# STM32WL5X_CM0P register map
File version: 2.1
CPU: CM0 r0p1, little endian, MPU, no FPU, 4 interrupt priority bits
Registers are 32-bit, read-write, reset 0x0 unless marked. A register's access mark holds for its fields unless they carry their own. Offsets are from the block's base; [hi:lo] are bit positions; {n}, {i} and the like mark numbered series; 'fields as' and 'values as' point back to an identical list.

## PWR — Power control
Base 0x58000400
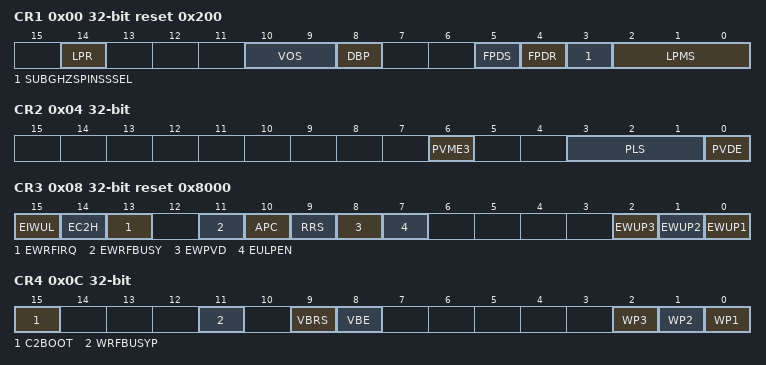
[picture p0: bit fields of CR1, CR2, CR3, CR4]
0x00 CR1 reset 0x200 — Power control register 1
  [14] LPR — Low-power run
    0=MainMode (Voltage regulator in Main mode in Low-power run mode); 1=LowPowerMode (Voltage regulator in low-power mode in Low-power run mode)
  [10:9] VOS — Voltage scaling range selection
    1=V1_2 (1.2 V (range 1)); 2=V1_0 (1.0 V (range 2))
  [8] DBP — Disable backup domain write protection
    0=Disabled (Access to RTC and backup registers disabled); 1=Enabled (Access to RTC and backup registers enabled)
  [5] FPDS — Flash memory power down mode during LPSleep for CPU1
    0=Idle (Flash memory in Idle mode when system is in LPSleep mode); 1=PowerDown (Flash memory in Power-down mode when system is in LPSleep mode)
  [4] FPDR — Flash memory power down mode during LPRun for CPU1
    0=Idle (Flash memory in Idle mode when system is in LPRun mode); 1=PowerDown (Flash memory in Power-down mode when system is in LPRun mode)
  [3] SUBGHZSPINSSSEL — sub-GHz SPI NSS source select
    0=SUBGHZSPICR (sub-GHz SPI NSS signal driven from PWR_SUBGHZSPICR.NSS (RFBUSYMS functionality enabled)); 1=LPTIM3 (sub-GHz SPI NSS signal driven from LPTIM3_OUT (RFBUSYMS functionality disabled))
  [2:0] LPMS — Low-power mode selection for CPU1
    0=Stop 0 mode; 1=Stop 1 mode; 2=Stop 2 mode; 3=Standby mode; 4=Shutdown mode
0x04 CR2 — Power control register 2
  [6] PVME3 — Peripheral voltage monitoring 3 enable: VDDA vs. 1.62V
    0=Disabled (PVM3 (VDDA monitoring versus 1.62 V threshold) disable); 1=Enabled (PVM3 (VDDA monitoring versus 1.62 V threshold) enable)
  [3:1] PLS — Power voltage detector level selection.
    0=V2_0 (2.0V); 1=V2_2 (2.2V); 2=V2_4 (2.4V); 3=V2_5 (2.5V); 4=V2_6 (2.6V); 5=V2_8 (2.8V); 6=V2_9 (2.9V); 7=External input analog voltage PVD_IN (compared internally to VREFINT)
  [0] PVDE — Power voltage detector enable
    0=Disabled (PVD Disabled); 1=Enabled (PVD Enabled)
0x08 CR3 reset 0x8000 — Power control register 3
  [15] EIWUL — Enable internal wakeup line for CPU1
    0=Disabled (Internal wakeup line interrupt to CPU1 disabled); 1=Enabled (Internal wakeup line interrupt to CPU1 enabled)
  [14] EC2H — nable CPU2 Hold interrupt for CPU1
  [13] EWRFIRQ — akeup for CPU1
    0=Disabled (Radio IRQ[2:0] is disabled and does not trigger a wakeup from Standby event to CPU1.); 1=Enabled (Radio IRQ[2:0] is enabled and triggers a wakeup from Standby event to CPU1.)
  [11] EWRFBUSY — Enable Radio BUSY Wakeup from Standby for CPU1
    0=Disabled (Radio Busy is disabled and does not trigger a wakeup from Standby event to CPU1 when a rising or a falling edge occurs); 1=Enabled (Radio Busy is enabled and triggers a wakeup from Standby event to CPU1 when a rising or a falling edge occurs. The active edge is configured via the WRFBUSYP bit in PWR_CR4)
  [10] APC — Apply pull-up and pull-down configuration from CPU1
    0=Disabled (I/O pull-up and pull-down configurations defined in the PWR_PUCRx and PWR_PDCRx registers are applied); 1=Enabled (PWR_PUCRx and PWR_PDCRx registers are NOT applied to the I/Os)
  [9] RRS — SRAM2 retention in Standby mode
    0=PowerOff (SRAM2 powered off in Standby mode (SRAM2 content lost)); 1=OnLPR (SRAM2 powered by the low-power regulator in Standby mode (SRAM2 content kept))
  [8] EWPVD — Enable wakeup PVD for CPU1
    0=Disabled (PVD not enabled by the sub-GHz radio active state); 1=Enabled (PVD enabled while the sub-GHz radio is active)
  [7] EULPEN — Ultra-low-power enable
    0=Disabled (Disable (the supply voltage is monitored continuously)); 1=Enabled (Enable, when set, the supply voltage is sampled for PDR/BOR reset condition only periodically)
  [2] EWUP3 — Enable Wakeup pin WKUP3 for CPU1
    0=Disabled (WKUP pin 3 is used for general purpose I/Os. An event on the WKUP pin 3 does not wakeup the device from Standby mode); 1=Enabled (WKUP pin 3 is used for wakeup from Standby mode and forced in input pull down configuration (rising edge on WKUP pin 3wakes-up the system from Standby mode))
  [1] EWUP2 — Enable Wakeup pin WKUP2 for CPU1
    0=Disabled (WKUP pin 2 is used for general purpose I/Os. An event on the WKUP pin 2 does not wakeup the device from Standby mode); 1=Enabled (WKUP pin 2 is used for wakeup from Standby mode and forced in input pull down configuration (rising edge on WKUP pin 2 wakes-up the system from Standby mode))
  [0] EWUP1 — Enable Wakeup pin WKUP1 for CPU1
    0=Disabled (WKUP pin 1 is used for general purpose I/Os. An event on the WKUP pin 1 does not wakeup the device from Standby mode); 1=Enabled (WKUP pin 1 is used for wakeup from Standby mode and forced in input pull down configuration (rising edge on WKUP pin 1 wakes-up the system from Standby mode))
0x0C CR4 — Power control register 4
  [15] C2BOOT — oot CPU2 after reset or wakeup from Stop or Standby modes.
  [11] WRFBUSYP — Wakeup Radio BUSY polarity
    0=RisingEdge (Detection on high level (rising edge)); 1=FallingEdge (Detection on low level (falling edge))
  [9] VBRS — VBAT battery charging resistor selection
    0=R5k (VBAT charging through a 5 kΩ resistor); 1=R1_5k (VBAT charging through a 1.5 kΩ resistor)
  [8] VBE — VBAT battery charging enable
    0=Disabled (VBAT battery charging disabled); 1=Enabled (VBAT battery charging enabled)
  [2] WP3 — Wakeup pin WKUP3 polarity
    values as WRFBUSYP
  [1] WP2 — Wakeup pin WKUP2 polarity
    values as WRFBUSYP
  [0] WP1 — Wakeup pin WKUP1 polarity
    values as WRFBUSYP
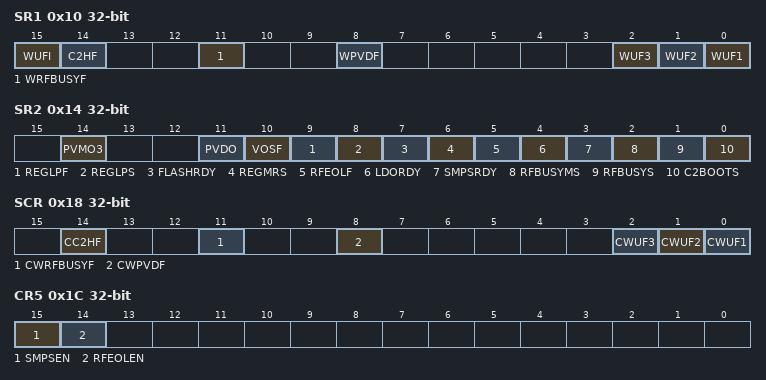
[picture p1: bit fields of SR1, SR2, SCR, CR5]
0x10 SR1 ro — Power status register 1
  [15] WUFI — Internal wakeup interrupt flag
    0=Clear (All internal wakeup sources are cleared); 1=wakeup is detected on the internal wakeup line
  [14] C2HF — PU2 Hold interrupt flag
  [11] WRFBUSYF — Radio BUSY wakeup flag
    0=Clear (No wakeup event detected on radio busy); 1=Wakeup event detected on radio busy
  [8] WPVDF — Wakeup PVD flag
    0=Clear (No wakeup event detected on PVD); 1=Wakeup event detected on PVD
  [2] WUF3 — Wakeup flag 3
    0=Clear (No wakeup event detected on WKUP3); 1=Wakeup event detected on WKUP3
  [1] WUF2 — Wakeup flag 2
    0=Clear (No wakeup event detected on WKUP2); 1=Wakeup event detected on WKUP2
  [0] WUF1 — Wakeup flag 1
    0=Clear (No wakeup event detected on WKUP1); 1=Wakeup event detected on WKUP1
0x14 SR2 ro — Power status register 2
  [14] PVMO3 — Peripheral voltage monitoring output: VDDA vs. 1.62 V
    0=Above (VDDA voltage above PVM3 threshold (around 1.62 V)); 1=Below (VDDA voltage below PVM3 threshold (around 1.62 V))
  [11] PVDO — Power voltage detector output
    0=Above (VDD or voltage level on PVD_IN above the selected PVD threshold); 1=Below (VDD or voltage level on PVD_IN below the selected PVD threshold)
  [10] VOSF — Voltage scaling flag
    0=Ready (Regulator ready in the selected voltage range); 1=Change (Regulator output voltage changed to the required voltage level)
  [9] REGLPF — regulator1 low power flag
    0=Main regulator (MR) ready and used; 1=Low-power regulator (LPR) used
  [8] REGLPS — regulator1 started
    0=NotReady (LPR not ready); 1=Ready (LPR ready)
  [7] FLASHRDY — Flash ready
    0=NotReady (Flash memory not ready to be accessed); 1=Ready (Flash memory ready to be accessed)
  [6] REGMRS — regulator2 low power flag
    0=V_DD (Main regulator supplied directly from VDD); 1=LDO_SMPS (Main regulator supplied through LDO or SMPS)
  [5] RFEOLF — Radio end of life flag
    0=Above (Supply voltage above radio end-of-life operating low level); 1=Below (Supply voltage below radio end-of-life operating low level)
  [4] LDORDY — LDO ready flag
    0=NotReady (LDO not ready or off); 1=Ready (LDO ready)
  [3] SMPSRDY — SMPS ready flag
    0=NotReady (SMPS step-down converter not ready or off); 1=Ready (SMPS step-down converter ready)
  [2] RFBUSYMS — Radio BUSY masked signal status
    0=NotBusy (radio busy masked signal low (not busy)); 1=Busy (radio busy masked signal high (busy))
  [1] RFBUSYS — Radio BUSY signal status
    0=NotBusy (radio busy signal low (not busy)); 1=Busy (radio busy signal high (busy))
  [0] C2BOOTS — PU2 boot/wakeup request source information
0x18 SCR wo — Power status clear register
  [14] CC2HF — lear CPU2 Hold interrupt flag
  [11] CWRFBUSYF — Clear wakeup Radio BUSY flag
    1=Clear (Setting this bit clears the WRFBUSYF flag in the PWR_SR1. This bit is always read 0.)
  [8] CWPVDF — Clear wakeup PVD interrupt flag
    1=Clear (Setting this bit clears the WPVDF flag in the PWR_SR1. This bit is always read as 0.)
  [2] CWUF3 — Clear wakeup flag 3
    1=Clear (Setting this bit clears the WUF3 flag in the PWR_SR1 register. This bit is always read as 0.)
  [1] CWUF2 — Clear wakeup flag 2
    1=Clear (Setting this bit clears the WUF2 flag in the PWR_SR1 register. This bit is always read as 0.)
  [0] CWUF1 — Clear wakeup flag 1
    1=Clear (Setting this bit clears the WUF1 flag in the PWR_SR1 register. This bit is always read as 0.)
0x1C CR5 — Power control register 5
  [15] SMPSEN — Enable SMPS Step Down converter SMPS mode enabled.
    0=Disabled (SMPS step-down converter SMPS mode disabled (LDO mode enabled)); 1=Enabled (SMPS step-down converter SMPS mode enabled)
  [14] RFEOLEN — Enable Radio End Of Life detector enabled
    0=Disabled (Radio end-of-life detector disabled); 1=Enabled (Radio end-of-life detector enabled)
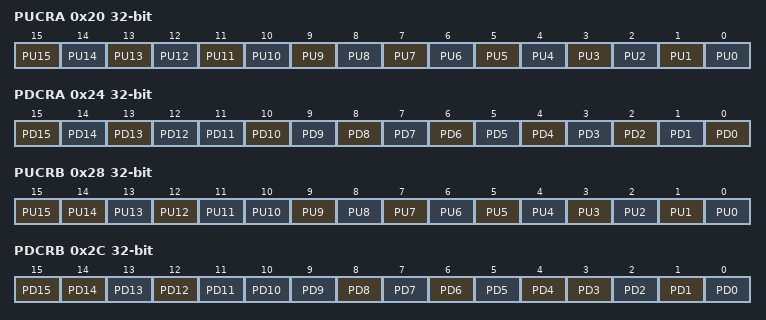
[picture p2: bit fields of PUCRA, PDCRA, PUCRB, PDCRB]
0x20 PUCRA — Power Port A pull-up control register
  [all] fields
    0=Disabled (Disable pull-up on PA[y] when both APC bits are set in PWR control register 3 (PWR_CR3)); 1=Enabled (Enable pull-up on PA[y] when both APC bits are set in PWR control register 3 (PWR_CR3). The pull-up is not activated if the corresponding PA[y] bit is also set)
  [15] PU15 — Port PA15 pull-up
  [14] PU14
  [13] PU13 — Port PA[y] pull-up bit y (y=0 to 13)
  [n] PU{n} (n=0..12)
0x24 PDCRA — Power Port A pull-down control register
  [all] fields
    0=Disabled (Disable the pull-down on PA[y] when both APC bits are set in PWR control register 3 (PWR_CR3)); 1=Enabled (Enable the pull-down on PA[y] when both APC bits are set in PWR control register 3 (PWR_CR3))
  [15] PD15
  [14] PD14 — ull-down
  [13] PD13
  [12] PD12 — Port PA[y] pull-down (y=0 to 12)
  [n] PD{n} (n=0..11)
0x28 PUCRB — Power Port B pull-up control register
  [15] PU15 — Port PB[y] pull-up (y=0 to 15)
    values as the fields of PUCRA
  [n] PU{n} (n=11..14)
    values as the fields of PUCRA
  [10] PU10
    0=Disabled (Disable pull-up on PB[y] when both APC bits are set in PWR control register 3 (PWR_CR3)); 1=Enabled (Enable pull-up on PB[y] when both APC bits are set in PWR control register 3 (PWR_CR3). The pull-up is not activated if the corresponding PB[y] bit is also set)
  [n] PU{n} (n=1..9)
    values as the fields of PUCRA
  [0] PU0
    values as PU10
0x2C PDCRB — Power Port B pull-down control register
  [15] PD15 — Port PB[y] pull-down (y=5 to 15)
    values as the fields of PDCRA
  [n] PD{n} (n=11..14)
    values as the fields of PDCRA
  [10] PD10
    0=Disabled (Disable the pull-down on PB[y] when both APC bits are set in PWR control register 3 (PWR_CR3)); 1=Enabled (Enable the pull-down on PB[y] when both APC bits are set in PWR control register 3 (PWR_CR3))
  [n] PD{n} (n=4..9)
    values as the fields of PDCRA
  [3] PD3 — Port PB[y] pull-down (y=0 to 3)
    values as the fields of PDCRA
  [2] PD2
    values as the fields of PDCRA
  [1] PD1
    values as the fields of PDCRA
  [0] PD0
    values as PD10
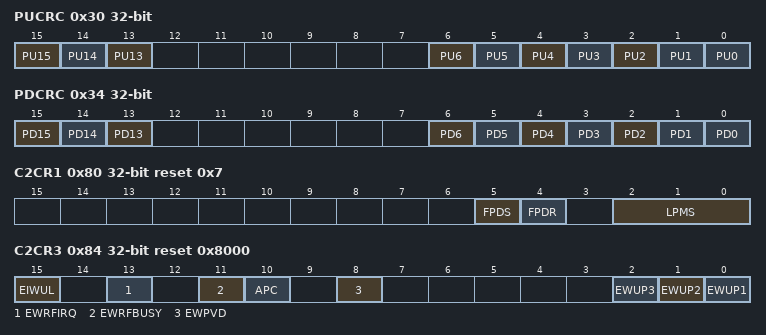
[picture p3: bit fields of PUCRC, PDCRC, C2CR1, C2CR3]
0x30 PUCRC — Power Port C pull-up control register
  [15] PU15 — Port PC[y] pull-up (y=13 to 15)
    0=Disabled (Disable pull-up on PC[y] when both APC bits are set in PWR control register 3 (PWR_CR3)); 1=Enabled (Enable pull-up on PC[y] when both APC bits are set in PWR control register 3 (PWR_CR3). The pull-up is not activated if the corresponding PC[y] bit is also set)
  [14] PU14
    values as PU15
  [13] PU13
    values as PU15
  [n] PU{n} (n=1..6)
    values as the fields of PUCRA
  [0] PU0
    values as PU15
0x34 PDCRC — Power Port C pull-down control register
  [15] PD15 — Port PC[y] pull-down (y=13 to 15)
    0=Disabled (Disable the pull-down on PC[y] when both APC bits are set in PWR control register 3 (PWR_CR3)); 1=Enabled (Enable the pull-down on PC[y] when both APC bits are set in PWR control register 3 (PWR_CR3))
  [14] PD14
    values as PD15
  [13] PD13
    values as PD15
  [n] PD{n} (n=1..6)
    values as the fields of PDCRA
  [0] PD0
    values as PD15
0x58 PUCRH — Power Port H pull-up control register
  [3] PU3 — pull-up
    0=Disabled (Disable pull-up on PH[y] when both APC bits are set in PWR control register 3 (PWR_CR3)); 1=Enabled (Enable pull-up on PH[y] when both APC bits are set in PWR control register 3 (PWR_CR3). The pull-up is not activated if the corresponding PH[y] bit is also set)
0x5C PDCRH — Power Port H pull-down control register
  [3] PD3 — pull-down
    0=Disabled (Disable the pull-down on PH[y] when both APC bits are set in PWR control register 3 (PWR_CR3)); 1=Enabled (Enable the pull-down on PH[y] when both APC bits are set in PWR control register 3 (PWR_CR3))
0x80 C2CR1 reset 0x7 — Power CPU2 control register 1 [dual core device only]
  [5] FPDS — Flash memory power down mode during LPSleep for CPU2
    values as CR1.FPDS
  [4] FPDR — Flash memory power down mode during LPRun for CPU2
    values as CR1.FPDR
  [2:0] LPMS — Low-power mode selection for CPU2
    values as CR1.LPMS
0x84 C2CR3 reset 0x8000 — Power CPU2 control register 3 [dual core device only]
  [15] EIWUL — Enable internal wakeup line for CPU2
    0=Disabled (Internal wakeup line interrupt to CPU2 disabled); 1=Enabled (Internal wakeup line interrupt to CPU2 enabled)
  [13] EWRFIRQ — akeup for CPU2
    0=Disabled (Radio IRQ[2:0] is disabled and does not trigger a wakeup from Standby event to CPU2.); 1=Enabled (Radio IRQ[2:0] is enabled and triggers a wakeup from Standby event to CPU2.)
  [11] EWRFBUSY
    0=Disabled (Radio Busy is disabled and does not trigger a wakeup from Standby event to CPU2 when a rising or a falling edge occurs); 1=Enabled (Radio Busy is enabled and triggers a wakeup from Standby event to CPU2 when a rising or a falling edge occurs. The active edge is configured via the WRFBUSYP bit in PWR_CR4)
  [10] APC — Apply pull-up and pull-down configuration for CPU2
    values as CR3.APC
  [8] EWPVD — Enable wakeup PVD for CPU2
    values as CR3.EWPVD
  [2] EWUP3 — Enable Wakeup pin WKUP3 for CPU2
    values as CR3.EWUP3
  [1] EWUP2 — Enable Wakeup pin WKUP2 for CPU2
    values as CR3.EWUP2
  [0] EWUP1 — Enable Wakeup pin WKUP1 for CPU2
    values as CR3.EWUP1
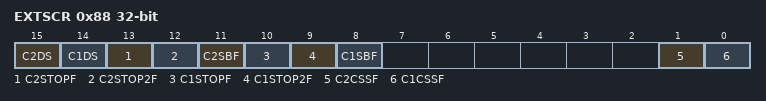
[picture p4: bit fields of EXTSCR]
0x88 EXTSCR access per field — Power extended status and status clear register
  [15] C2DS ro — PU2 deepsleep mode
  [14] C1DS ro — CPU1 deepsleep mode
    0=RunningOrSleep (CPU is running or in sleep); 1=DeepSleep (CPU is in Deep-Sleep)
  [13] C2STOPF ro — ystem Stop0, 1 flag for CPU2. (All core states retained)
  [12] C2STOP2F ro — ystem Stop2 flag for CPU2. (partial core states retained)
  [11] C2SBF ro — ystem Standby flag for CPU2. (no core states retained)
  [10] C1STOPF ro — System Stop0, 1 flag for CPU1. (All core states retained)
    0=NoStop (System has not been in Stop 0 or 1 mode); 1=Stop (System has been in Stop 0 or 1 mode)
  [9] C1STOP2F ro — System Stop2 flag for CPU1. (partial core states retained)
    0=NoStop (System has not been in Stop 2 mode); 1=Stop (System has been in Stop 2 mode)
  [8] C1SBF ro — System Standby flag for CPU1. (no core states retained)
    0=NoStandby (System has not been in Standby mode); 1=Standby (System has been in Standby mode)
  [1] C2CSSF wo — lear CPU2 Stop Standby flags
  [0] C1CSSF wo — Clear CPU1 Stop Standby flags
    1=Clear (Setting this bit clears the C1STOPF and C1SBF bits)
0x8C SECCFGR reset 0x8000 — Power security configuration register [dual core device only]
  [15] C2EWILA — wakeup on CPU2 illegal access interrupt enable
0x90 SUBGHZSPICR reset 0x8000 — Power SPI3 control register
  [15] NSS — sub-GHz SPI NSS control
    0=Low (Sub-GHz SPI NSS signal at level low); 1=High (Sub-GHz SPI NSS signal is at level high)
0x98 RSSCMDR — RSS Command register [dual core device only]
  [7:0] RSSCMD — RSS command
